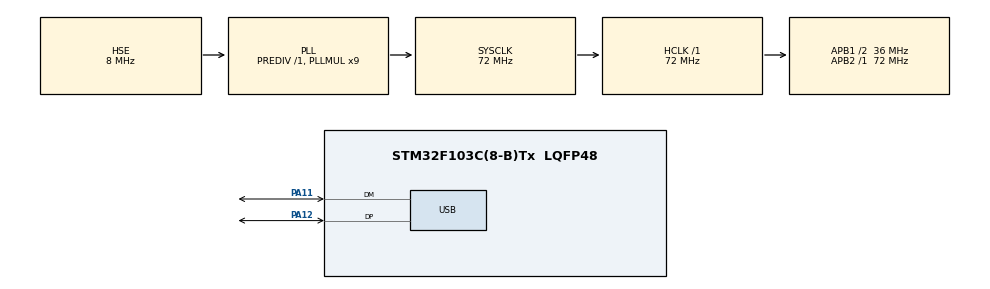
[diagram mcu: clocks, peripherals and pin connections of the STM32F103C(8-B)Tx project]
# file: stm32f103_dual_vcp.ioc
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Mcu.Family=STM32F1
Mcu.Name=STM32F103C(8-B)Tx
Mcu.Package=LQFP48
NVIC.PriorityGroup=NVIC_PRIORITYGROUP_4
NVIC.USB_LP_CAN1_RX0_IRQn=true\:0\:0\:false\:false\:true\:true\:true\:true
PA11.Mode=Device
PA11.Signal=USB_DM
PA12.Mode=Device
PA12.Signal=USB_DP
PA13.Mode=Serial_Wire
PA13.Signal=SYS_JTMS-SWDIO
PA14.Mode=Serial_Wire
PA14.Signal=SYS_JTCK-SWCLK
PD0-OSC_IN.Mode=HSE-External-Oscillator
PD0-OSC_IN.Signal=RCC_OSC_IN
PD1-OSC_OUT.Mode=HSE-External-Oscillator
PD1-OSC_OUT.Signal=RCC_OSC_OUT
ProjectManager.HeapSize=0x800
ProjectManager.StackSize=0x800
ProjectManager.TargetToolchain=STM32CubeIDE
RCC.AHBFreq_Value=72000000
RCC.APB1CLKDivider=RCC_HCLK_DIV2
RCC.APB1Freq_Value=36000000
RCC.APB1TimFreq_Value=72000000
RCC.APB2Freq_Value=72000000
RCC.APB2TimFreq_Value=72000000
RCC.HCLKFreq_Value=72000000
RCC.PLLMUL=RCC_PLL_MUL9
RCC.SYSCLKFreq_VALUE=72000000
RCC.SYSCLKSource=RCC_SYSCLKSOURCE_PLLCLK
RCC.USBFreq_Value=48000000
RCC.USBPrescaler=RCC_USBCLKSOURCE_PLL_DIV1_5
USB_DEVICE.APP_RX_DATA_SIZE=512
USB_DEVICE.APP_TX_DATA_SIZE=512
USB_DEVICE.CLASS_NAME_FS=CDC
USB_DEVICE.MANUFACTURER_STRING=Dev.Idv
USB_DEVICE.PID_CDC_FS=3001
USB_DEVICE.PRODUCT_STRING_CDC_FS=DualPort
USB_DEVICE.USBD_MAX_NUM_INTERFACES=2
USB_DEVICE.USBD_SELF_POWERED=0
USB_DEVICE.VID=0x3483
USB_DEVICE.VirtualMode=Cdc
USB_DEVICE.VirtualModeFS=Cdc_FS
VP_USB_DEVICE_VS_USB_DEVICE_CDC_FS.Mode=CDC_FS
board=custom

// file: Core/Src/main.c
/* USER CODE BEGIN Header */
/**
  ******************************************************************************
  * @file           : main.c
  * @brief          : Main program body
  ******************************************************************************
  * @attention
  *
  * Copyright (c) 2025 STMicroelectronics.
  * All rights reserved.
  *
  * This software is licensed under terms that can be found in the LICENSE file
  * in the root directory of this software component.
  * If no LICENSE file comes with this software, it is provided AS-IS.
  *
  ******************************************************************************
  */
/* USER CODE END Header */
#include "main.h"
#include "usb_device.h"
#include "gpio.h"

/* USER CODE BEGIN Includes */
#include "usbd_cdc_if.h"
/* USER CODE END Includes */

void SystemClock_Config(void);
/* USER CODE BEGIN PFP */

void USB_CDC_RxHandler_0(uint8_t*, uint32_t);
void USB_CDC_RxHandler_2(uint8_t*, uint32_t);

/* USER CODE END PFP */

int main(void)
{

  /* MCU Configuration--------------------------------------------------------*/

  /* Reset of all peripherals, Initializes the Flash interface and the Systick. */
  HAL_Init();

  /* Configure the system clock */
  SystemClock_Config();

  /* Initialize all configured peripherals */
  MX_GPIO_Init();
  MX_USB_DEVICE_Init();
  /* USER CODE BEGIN 2 */

  HAL_NVIC_SetPriorityGrouping(NVIC_PRIORITYGROUP_2);
  HAL_NVIC_SetPriority(USB_HP_CAN1_TX_IRQn  , 0, 2);
  HAL_NVIC_SetPriority(USB_LP_CAN1_RX0_IRQn , 0, 3);
  /* USER CODE END 2 */

  /* Infinite loop */
  while (1)
  {

    /* USER CODE BEGIN 3 */

		 while (CDC_Transmit_FS("USB0_N\r\n", 8, 0) == USBD_BUSY){};
		  HAL_Delay(1000);
		while (CDC_Transmit_FS("USB2_N\r\n", 8, 2) == USBD_BUSY){};
		  HAL_Delay(1000);

  }
  /* USER CODE END 3 */
}

void SystemClock_Config(void)
{
  RCC_OscInitTypeDef RCC_OscInitStruct = {0};
  RCC_ClkInitTypeDef RCC_ClkInitStruct = {0};
  RCC_PeriphCLKInitTypeDef PeriphClkInit = {0};

  /** Initializes the RCC Oscillators according to the specified parameters
  * in the RCC_OscInitTypeDef structure.
  */
  RCC_OscInitStruct.OscillatorType = RCC_OSCILLATORTYPE_HSE;
  RCC_OscInitStruct.HSEState = RCC_HSE_ON;
  RCC_OscInitStruct.HSEPredivValue = RCC_HSE_PREDIV_DIV1;
  RCC_OscInitStruct.HSIState = RCC_HSI_ON;
  RCC_OscInitStruct.PLL.PLLState = RCC_PLL_ON;
  RCC_OscInitStruct.PLL.PLLSource = RCC_PLLSOURCE_HSE;
  RCC_OscInitStruct.PLL.PLLMUL = RCC_PLL_MUL9;
  if (HAL_RCC_OscConfig(&RCC_OscInitStruct) != HAL_OK)
  {
    Error_Handler();
  }

  /** Initializes the CPU, AHB and APB buses clocks
  */
  RCC_ClkInitStruct.ClockType = RCC_CLOCKTYPE_HCLK|RCC_CLOCKTYPE_SYSCLK
                              |RCC_CLOCKTYPE_PCLK1|RCC_CLOCKTYPE_PCLK2;
  RCC_ClkInitStruct.SYSCLKSource = RCC_SYSCLKSOURCE_PLLCLK;
  RCC_ClkInitStruct.AHBCLKDivider = RCC_SYSCLK_DIV1;
  RCC_ClkInitStruct.APB1CLKDivider = RCC_HCLK_DIV2;
  RCC_ClkInitStruct.APB2CLKDivider = RCC_HCLK_DIV1;

  if (HAL_RCC_ClockConfig(&RCC_ClkInitStruct, FLASH_LATENCY_2) != HAL_OK)
  {
    Error_Handler();
  }
  PeriphClkInit.PeriphClockSelection = RCC_PERIPHCLK_USB;
  PeriphClkInit.UsbClockSelection = RCC_USBCLKSOURCE_PLL_DIV1_5;
  if (HAL_RCCEx_PeriphCLKConfig(&PeriphClkInit) != HAL_OK)
  {
    Error_Handler();
  }
}

/* USER CODE BEGIN 4 */
/**
  * @brief  This function is executed in case of error occurrence.
  * @param  file: The file name as string.
  * @param  line: The line in file as a number.
  * @retval None
  */
void _Error_Handler(char *file, int line)
{
  /* USER CODE BEGIN Error_Handler_Debug */
  /* User can add his own implementation to report the HAL error return state */
/*  while(1)
  {
    printf("_Error_Handler: %s #%d\n", file, line);
    HAL_Delay(1000);
  }*/
  /* USER CODE END Error_Handler_Debug */
}

void USB_CDC_RxHandler_0(uint8_t* Buf, uint32_t Len)
{
	while (CDC_Transmit_FS(Buf, Len, 0) == USBD_BUSY){};

}
void USB_CDC_RxHandler_2(uint8_t* Buf, uint32_t Len)
{
	while (CDC_Transmit_FS(Buf, Len, 2) == USBD_BUSY){};

}

/* USER CODE END 4 */

void Error_Handler(void)
{
  /* USER CODE BEGIN Error_Handler_Debug */
  /* User can add his own implementation to report the HAL error return state */
/*  while(1)
  {
    printf("_Error_Handler: %s #%d\n", file, line);
    HAL_Delay(1000);
  }*/
  /* USER CODE END Error_Handler_Debug */
}
